AUTOSAR XML (schema 4-0-3)
package /AUTOSAR_BswM  # Basic Software Mode Manager
package /AUTOSAR_BswM/units
  unit DummyUnit
package /AUTOSAR_BswM/SwComponentTypes
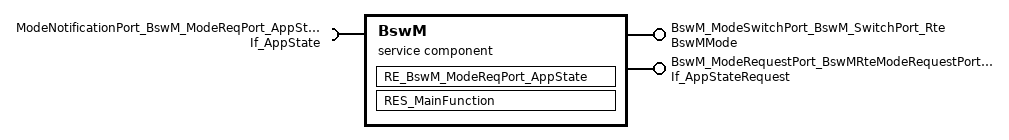
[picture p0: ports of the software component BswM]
  service sw component type BswM
    provide port BswM_ModeSwitchPort_BswM_SwitchPort_Rte: mode-switch-sender-com-spec{mode-group=CurrentMode, queue-length=5}, provided-interface=BswMMode
    provide port BswM_ModeRequestPort_BswMRteModeRequestPort_AppStateMode: provided-interface=If_AppStateRequest
    require port ModeNotificationPort_BswM_ModeReqPort_AppState: mode-switch-receiver-com-spec{enhanced-mode-api=1, supports-asynchronous-mode-switch=0}, required-interface=If_AppState
    behavior BswMInternalBehavior: data-type-mapping=[BswMModeMapping, ModeMapping, DataTypeMappingSet_0, AppModeMapping], handle-termination-and-restart=CAN-BE-TERMINATED-AND-RESTARTED
      5 x swc mode switch event, all with start-on-event=RE_BswM_ModeReqPort_AppState, activation=ON-ENTRY:
        MSE_BswM_ModeReqPort_AppState_EB_INTGR_APP_STARTUP: mode=ModeNotificationPort_BswM_ModeReqPort_AppState.AppStateMode.EB_INTGR_APP_STARTUP
        MSE_BswM_ModeReqPort_AppState_EB_INTGR_APP_ACTIVE: mode=ModeNotificationPort_BswM_ModeReqPort_AppState.AppStateMode.EB_INTGR_APP_ACTIVE
        MSE_BswM_ModeReqPort_AppState_EB_INTGR_APP_INACTIVE: mode=ModeNotificationPort_BswM_ModeReqPort_AppState.AppStateMode.EB_INTGR_APP_INACTIVE
        MSE_BswM_ModeReqPort_AppState_EB_INTGR_APP_SLEEP: mode=ModeNotificationPort_BswM_ModeReqPort_AppState.AppStateMode.EB_INTGR_APP_SLEEP
        MSE_BswM_ModeReqPort_AppState_EB_INTGR_APP_WAKEUP: mode=ModeNotificationPort_BswM_ModeReqPort_AppState.AppStateMode.EB_INTGR_APP_WAKEUP
      included-mode-declaration-group-sets:
        mode-declaration-group=AppStateModeGroup, prefix=BSWM_
        mode-declaration-group=DcmCommunicationControl, prefix=BSWM_
        mode-declaration-group=ComMMode, prefix=BSWM_
        mode-declaration-group=DcmEcuReset, prefix=BSWM_
        mode-declaration-group=BswMModeGroup, prefix=BSWM_
      runnable RE_BswM_ModeReqPort_AppState: mode-access-point=ModeNotificationPort_BswM_ModeReqPort_AppState.AppStateMode, symbol=BswM_MRPFunc_BswM_ModeReqPort_AppState
      runnable RES_MainFunction: symbol=BswM_MainFunction
        data-send-points:
          access BSWM_VA_BswMRteModeRequestPort_AppStateMode: accessed-variable=BswM_ModeRequestPort_BswMRteModeRequestPort_AppStateMode.If_AppStateRequestMode
        mode switch point RES_MainFunction_to_BswM_SwitchPort_Rte: mode-group=BswM_ModeSwitchPort_BswM_SwitchPort_Rte.CurrentMode
package /AUTOSAR_BswM/SwcImplementations
  swc implementation BswMImplementation: programming-language=C, sw-version=1.1.1, vendor-id=1, behavior=BswMInternalBehavior
    code-descriptors:
      code BswMImplementationEB: artifact-descriptors=autosar-engineering-object={short-label=BswMEngObject, category=SWSRC}
    resource consumption Resources
      memory section CODE: sw-addrmethod=CODE
